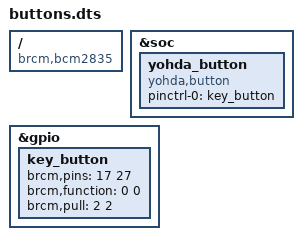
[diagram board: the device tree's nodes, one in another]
/dts-v1/;
/plugin/;

/*
// linux/include/dt-bindings/pinctrl/bcm2835.h
#ifndef __DT_BINDINGS_PINCTRL_BCM2835_H__
#define __DT_BINDINGS_PINCTRL_BCM2835_H__

// brcm,function property
#define BCM2835_FSEL_GPIO_IN    0
#define BCM2835_FSEL_GPIO_OUT   1
#define BCM2835_FSEL_ALT5   2
#define BCM2835_FSEL_ALT4   3
#define BCM2835_FSEL_ALT0   4
#define BCM2835_FSEL_ALT1   5
#define BCM2835_FSEL_ALT2   6
#define BCM2835_FSEL_ALT3   7

// brcm,pull property
#define BCM2835_PUD_OFF     0
#define BCM2835_PUD_DOWN    1
#define BCM2835_PUD_UP      2
*/

/ {
    compatible = "brcm,bcm2835";

	fragment@0 {
		target = <&soc>;
		__overlay__ {
			yohda_button {
				compatible = "yohda,button";			
			
				pinctrl-names = "default";
				pinctrl-0 = <&key_button>;
			};
		};
	};

	fragment@1 {
        target = <&gpio>;
        __overlay__ {
            key_button: key_button {
                brcm,pins = <17 27>;
                brcm,function = <0 0>;
                brcm,pull = <2 2>;    
            };    
        };
    };	
};
